AUTOSAR XML (schema 4-0-3)
package /ComponentTypes
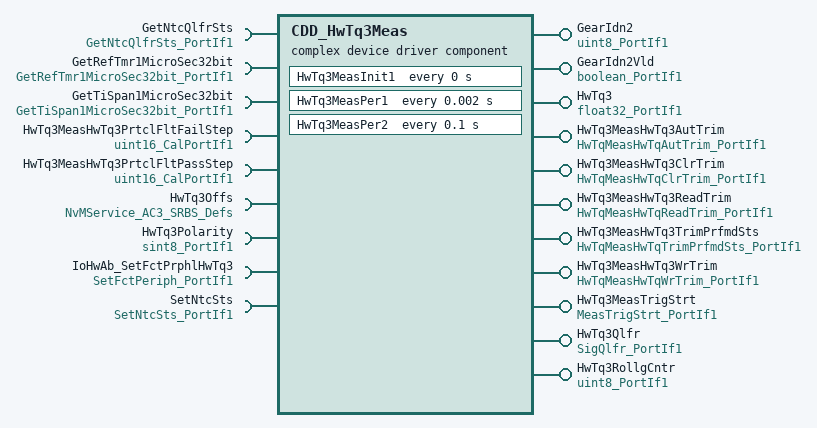
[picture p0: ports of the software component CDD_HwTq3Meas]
  complex device driver sw component type CDD_HwTq3Meas
    11 x provide port:
      GearIdn2: nonqueued-sender-com-spec{data-element=Val, init-value=0}, provided-interface=uint8_PortIf1
      GearIdn2Vld: nonqueued-sender-com-spec{data-element=Logl, init-value=0}, provided-interface=boolean_PortIf1
      HwTq3: nonqueued-sender-com-spec{data-element=Val, init-value=0}, provided-interface=float32_PortIf1
      HwTq3MeasHwTq3AutTrim: server-com-spec{operation=Oper, queue-length=1}, provided-interface=HwTqMeasHwTqAutTrim_PortIf1
      HwTq3MeasHwTq3ClrTrim: server-com-spec{operation=Oper, queue-length=1}, provided-interface=HwTqMeasHwTqClrTrim_PortIf1
      HwTq3MeasHwTq3ReadTrim: server-com-spec{operation=Oper, queue-length=1}, provided-interface=HwTqMeasHwTqReadTrim_PortIf1
      HwTq3MeasHwTq3TrimPrfmdSts: server-com-spec{operation=Oper, queue-length=1}, provided-interface=HwTqMeasHwTqTrimPrfmdSts_PortIf1
      HwTq3MeasHwTq3WrTrim: server-com-spec{operation=Oper, queue-length=1}, provided-interface=HwTqMeasHwTqWrTrim_PortIf1
      HwTq3MeasTrigStrt: server-com-spec{operation=Oper, queue-length=1}, provided-interface=MeasTrigStrt_PortIf1
      HwTq3Qlfr: nonqueued-sender-com-spec{data-element=Val, init-value=0}, provided-interface=SigQlfr_PortIf1
      HwTq3RollgCntr: nonqueued-sender-com-spec{data-element=Val, init-value=0}, provided-interface=uint8_PortIf1
    9 x require port:
      GetNtcQlfrSts: required-interface=GetNtcQlfrSts_PortIf1
      GetRefTmr1MicroSec32bit: required-interface=GetRefTmr1MicroSec32bit_PortIf1
      GetTiSpan1MicroSec32bit: required-interface=GetTiSpan1MicroSec32bit_PortIf1
      HwTq3MeasHwTq3PrtclFltFailStep: parameter-require-com-spec{init-value=2521, parameter=Val}, required-interface=uint16_CalPortIf1
      HwTq3MeasHwTq3PrtclFltPassStep: parameter-require-com-spec{init-value=1000, parameter=Val}, required-interface=uint16_CalPortIf1
      HwTq3Offs: required-interface=NvMService_AC3_SRBS_Defs
      HwTq3Polarity: nonqueued-receiver-com-spec{data-element=Val, filter=data-filter-type=ALWAYS, init-value=1}, required-interface=sint8_PortIf1
      IoHwAb_SetFctPrphlHwTq3: required-interface=SetFctPeriph_PortIf1
      SetNtcSts: required-interface=SetNtcSts_PortIf1
    behavior CDD_HwTq3Meas_InternalBehavior
      ar-typed-per-instance-memorys:
        8 x data, all with sw-calibration-access=READ-ONLY:
          GearIdn2Avl: type=boolean
          GearIdn2Data: type=uint8
          HwTq3ComStsErrCntr: type=uint8
          HwTq3IntSnsrErrCntr: type=uint8
          HwTq3MeasPrevHwTq3: type=float32
          HwTq3MeasPrevRollgCntr: type=uint8
          HwTq3MsgMissRxCnt: type=uint32
          HwTq3Offs: type=HwTqOffsRec1
      5 x operation invoked event:
        OIT_HwTq3MeasHwTq3AutTrim_Oper_HwTq3MeasHwTq3AutTrim_Oper: start-on-event=HwTq3MeasHwTq3AutTrim_Oper, operation=HwTq3MeasHwTq3AutTrim.Oper
        OIT_HwTq3MeasHwTq3ClrTrim_Oper_HwTq3MeasHwTq3ClrTrim_Oper: start-on-event=HwTq3MeasHwTq3ClrTrim_Oper, operation=HwTq3MeasHwTq3ClrTrim.Oper
        OIT_HwTq3MeasHwTq3ReadTrim_Oper_HwTq3MeasHwTq3ReadTrim_Oper: start-on-event=HwTq3MeasHwTq3ReadTrim_Oper, operation=HwTq3MeasHwTq3ReadTrim.Oper
        OIT_HwTq3MeasHwTq3TrimPrfmdSts_Oper_HwTq3MeasHwTq3TrimPrfmdSts_Oper: start-on-event=HwTq3MeasHwTq3TrimPrfmdSts_Oper, operation=HwTq3MeasHwTq3TrimPrfmdSts.Oper
        OIT_HwTq3MeasHwTq3WrTrim_Oper_HwTq3MeasHwTq3WrTrim_Oper: start-on-event=HwTq3MeasHwTq3WrTrim_Oper, operation=HwTq3MeasHwTq3WrTrim.Oper
      timing event HwTq3MeasInit1_InitEvent: start-on-event=HwTq3MeasInit1, period=0
      timing event TMT_HwTq3MeasPer1: start-on-event=HwTq3MeasPer1, period=0.002
      timing event TMT_HwTq3MeasPer3: start-on-event=HwTq3MeasPer2, period=0.1
      operation invoked event OIT_HwTq3MeasTrigStrt_Oper_HwTq3MeasTrigStrt_Oper: start-on-event=HwTq3MeasTrigStrt_Oper, operation=HwTq3MeasTrigStrt.Oper
      9 x runnable:
        HwTq3MeasHwTq3AutTrim_Oper
          sync call SC_HwTq3Offs_SetRamBlockStatus: operation=HwTq3Offs.SetRamBlockStatus, timeout=0
        HwTq3MeasHwTq3ClrTrim_Oper
          sync call SC_HwTq3Offs_SetRamBlockStatus: operation=HwTq3Offs.SetRamBlockStatus, timeout=0
        HwTq3MeasHwTq3ReadTrim_Oper
        HwTq3MeasHwTq3TrimPrfmdSts_Oper
        HwTq3MeasHwTq3WrTrim_Oper
          sync call SC_HwTq3Offs_SetRamBlockStatus: operation=HwTq3Offs.SetRamBlockStatus, timeout=0
        HwTq3MeasInit1
          sync call SC_GetRefTmr1MicroSec32bit_Oper: operation=GetRefTmr1MicroSec32bit.Oper, timeout=0
          sync call SC_GetTiSpan1MicroSec32bit_Oper: operation=GetTiSpan1MicroSec32bit.Oper, timeout=0
          sync call SC_IoHwAb_SetFctPrphlHwTq2_Oper: operation=IoHwAb_SetFctPrphlHwTq3.Oper, timeout=0
        HwTq3MeasPer1
          data-receive-point-by-arguments:
            access REC_HwTq0Polarity_Val: accessed-variable=HwTq3Polarity.Val
          data-send-points:
            5 x access:
              SEND_GearIdn2_Val: accessed-variable=GearIdn2.Val
              SEND_GearIdn2Vld_Logl: accessed-variable=GearIdn2Vld.Logl
              SEND_HwTq0_Val: accessed-variable=HwTq3.Val
              SEND_HwTq0Qlfr_Val: accessed-variable=HwTq3Qlfr.Val
              SEND_HwTq0RollgCntr_Val: accessed-variable=HwTq3RollgCntr.Val
          sync call SC_GetNtcQlfrSts_Oper: operation=GetNtcQlfrSts.Oper, timeout=0
          sync call SC_SetNtcSts_Oper: operation=SetNtcSts.Oper, timeout=0
        HwTq3MeasPer2
          sync call SC_SetNtcSts_Oper: operation=SetNtcSts.Oper, timeout=0
        HwTq3MeasTrigStrt_Oper
          sync call SC_GetRefTmr1MicroSec32bit_Oper: operation=GetRefTmr1MicroSec32bit.Oper, timeout=0
          sync call SC_GetTiSpan1MicroSec32bit_Oper: operation=GetTiSpan1MicroSec32bit.Oper, timeout=0
      swc service dependency NvmHwTq3Offs: assigned-datas=[{role=ramBlock, used-data-element=HwTq3Offs}, {role=defaultValue, used-parameter-element=HwTq3OffsDft}]
        assigned-ports:
          port-prototype=HwTq3Offs, role=NvMService_AC3_SRBS_Defs
          port-prototype=HwTq3Offs, role=NvMService_AC3_SRBS_Defs
        service-needs:
          nv block needs NvmHwTq3Offs: n-data-sets=0, readonly=false, reliability=ERROR-DETECTION, resistant-to-changed-sw=true, restore-at-start=true, store-at-shutdown=true, write-only-once=false, writing-frequency=0, writing-priority=LOW
      shared-parameters:
        parameter data prototype HwTq3OffsDft: sw-calibration-access=READ-WRITE, type=HwTqOffsRec1, init-value=fields=[OffsTrim:0, OffsTrimPrfmdSts:0]
  swc implementation CDD_HwTq3Meas_Implementation: behavior=CDD_HwTq3Meas_InternalBehavior
    code-descriptors:
      code Default: artifact-descriptors=autosar-engineering-object={short-label=Default, category=SWSRC}
